# M311 register map
File version: 2.0.2.1
TOSHIBA Cortex-M3 MCU
Registers are 32-bit, read-write, reset 0x0 unless marked. A register's access mark holds for its fields unless they carry their own. Offsets are from the block's base; lines under a group give offsets from that group; [hi:lo] are bit positions; {n}, {i} and the like mark numbered series; 'fields as' and 'values as' point back to an identical list; <NAME> marks a mode.

## Memory map
0x40040000 SSP size 0x24 — Synchronous Serial Port (SSP)
0x4004C000 DMA blocks up to offset 0x50 — DMA Controller (DMA)
0x4005D000 TEMP size 0x8 — Temperature Sensor (TEMP)
0x40067000 DSADA blocks up to offset 0x48 — 24bit Delta Sigma AD Converter (DSAD)
0x40067400 DSADB blocks up to offset 0x48
0x40067800 DSADC blocks up to offset 0x48
0x40067C00 DSADD blocks up to offset 0x48
0x4008D000 T16A size 0x14 — 16-bit TimerA (T16A)
0x400B8000 INT blocks up to offset 0x4C — Interrupt Controller (INT)
0x400C0000 PA blocks up to offset 0x3C — Port A (PA)
0x400C0100 PB blocks up to offset 0x3C — Port B (PB)
0x400C0200 PC blocks up to offset 0x3C — Port C (PC)
0x400C0300 PD blocks up to offset 0x3C — Port D (PD)
0x400C4000 TB0 size 0x30 — 16-bit Timer_Event Counter (TB)
0x400C4100 TB1 size 0x30
0x400C4200 TB2 size 0x30
0x400C4300 TB3 size 0x30
0x400E1000 SC size 0x34 — SIO_UART (SC)
0x400F2000 WD size 0xC — Watchdog Timer (WD)
0x400F3000 CG blocks up to offset 0x28 — Clock Control (CG)

## SSP — Synchronous Serial Port (SSP)
Base 0x40040000
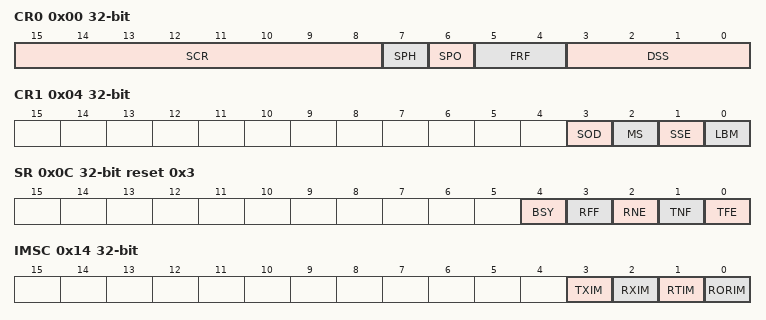
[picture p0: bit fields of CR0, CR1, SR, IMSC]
0x00 CR0 — SSP Control Register 0
  [15:8] SCR, [7] SPH, [6] SPO, [5:4] FRF, [3:0] DSS
0x04 CR1 — SSP Control Register 1
  [3] SOD, [2] MS, [1] SSE, [0] LBM
0x08 DR — SSP Data Register
  [15:0] DATA
0x0C SR ro reset 0x3 — SSP Status Register
  [4] BSY, [3] RFF, [2] RNE, [1] TNF, [0] TFE
0x10 CPSR — SSP Clock Prescaler Register
  [7:0] CPSDVSR
0x14 IMSC — SSP Interrupt Mask Set and Clear Register
  [3] TXIM, [2] RXIM, [1] RTIM, [0] RORIM
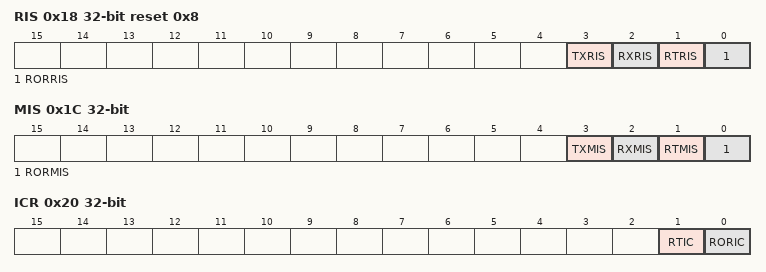
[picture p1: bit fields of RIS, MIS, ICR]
0x18 RIS ro reset 0x8 — SSP Raw Interrupt Status Register
  [3] TXRIS, [2] RXRIS, [1] RTRIS, [0] RORRIS
0x1C MIS ro — SSP Masked Interrupt Status Register
  [3] TXMIS, [2] RXMIS, [1] RTMIS, [0] RORMIS
0x20 ICR wo reset not defined — SSP Interrupt Clear Register
  [1] RTIC, [0] RORIC

## DMA — DMA Controller (DMA)
Base 0x4004C000
0x00 STATUS ro reset 0x101F0000 — DMA Status Register
  [0] MASTER_ENABLE
0x04 CFG wo reset not defined — DMA Configuration Register
  [0] MASTER_ENABLE
0x08 CTRLBASEPTR — DMA Control Data Base Pointer Register
  [31:10] CTRL_BASE_PTR
0x0C ALTCTRLBASEPTR ro — DMA Channel Alternate Control Data Base Pointer Register
  [31:0] ALT_CTRL_BASE_PTR
0x14 CHNLSWREQUEST wo reset not defined — DMA Channel Software Request Register
  [31:0] CHNL_SW_REQUEST
0x18 CHNLUSEBURSTSET — DMA Channel Useburst Set Register
  [31:0] CHNL_USEBURST_SET
0x1C CHNLUSEBURSTCLR wo reset not defined — DMA Channel Useburst Clear Register
  [31:0] CHNL_USEBURST_CLR
0x20 CHNLREQMASKSET — DMA Channel Request Mask Set Register
  [31:0] CHNL_REQ_MASK_SET
0x24 CHNLREQMASKCLR wo reset not defined — DMA Channel Request Mask Clear Register
  [31:0] CHNL_REQ_MASK_CLR
0x28 CHNLENABLESET — DMA Channel Enable Set Register
  [31:0] CHNL_ENABLE_SET
0x2C CHNLENABLECLR wo reset not defined — DMA Channel Enable Clear Register
  [31:0] CHNL_ENABLE_CLR
0x30 CHNLPRIALTSET — DMA Channel Primary-Alternate Set Register
  [31:0] CHNL_PRI_ALT_SET
0x34 CHNLPRIALTCLR wo reset not defined — DMA Channel Primary-Alternate Clear Register
  [31:0] CHNL_PRI_ALT_CLR
0x38 CHNLPRIORITYSET — DMA Channel Priority Set Register
  [31:0] CHNL_PRIORITY_SET
0x3C CHNLPRIORITYCLR wo reset not defined — DMA Channel Priority Clear Register
  [31:0] CHNL_PRIORITY_CLR
0x4C ERRCLR — DMA Bus Error Clear Register
  [0] ERR_CLR

## TEMP — Temperature Sensor (TEMP)
Base 0x4005D000
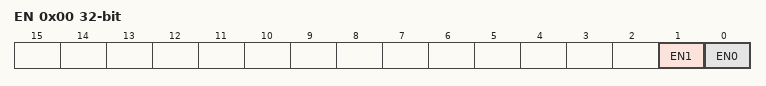
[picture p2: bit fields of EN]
0x00 EN — Enable Register
  [1] EN1, [0] EN0
0x04 CR — Control Register
  [0] CR0

## DSADA — 24bit Delta Sigma AD Converter (DSAD)
Base 0x40067000
Same registers: DSADB 0x40067400, DSADC 0x40067800, DSADD 0x40067C00
0x00 CLK — Conversion Clock Setting Register
  [2:0] ADCLK
0x04 CR0 — Control Register 0
  [1:0] ADRST wo
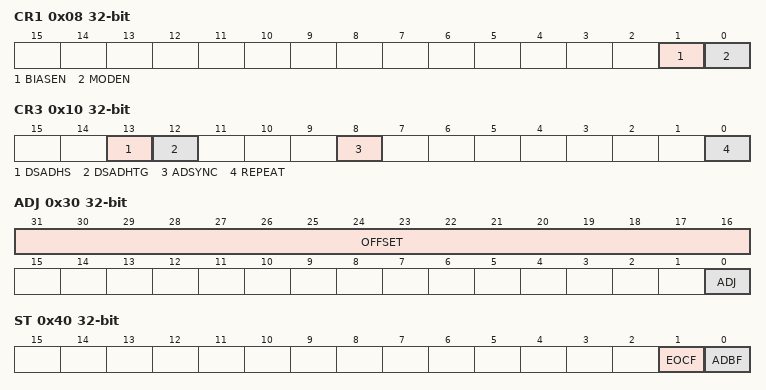
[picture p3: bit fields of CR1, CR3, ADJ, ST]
0x08 CR1 — Control Register 1
  [1] BIASEN, [0] MODEN
0x0C CR2 — Control Register 2
  [0] ADS wo
0x10 CR3 — Control Register 3
  [13] DSADHS, [12] DSADHTG, [8] ADSYNC, [0] REPEAT
0x14 CR4 — Control Register 4
  [2:0] DSGAIN
0x18 CR5 — Control Register 5
  [0] DSADCH
0x30 ADJ — Adjust Register
  [31:16] OFFSET, [0] ADJ
0x40 ST ro — Status Register
  [1] EOCF, [0] ADBF
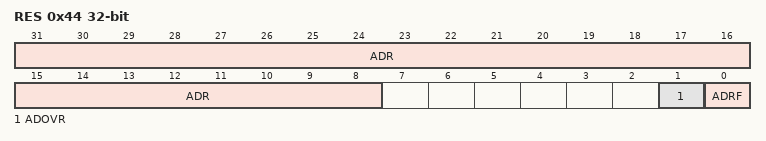
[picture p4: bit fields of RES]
0x44 RES ro — Result Register
  [31:8] ADR, [1] ADOVR, [0] ADRF
